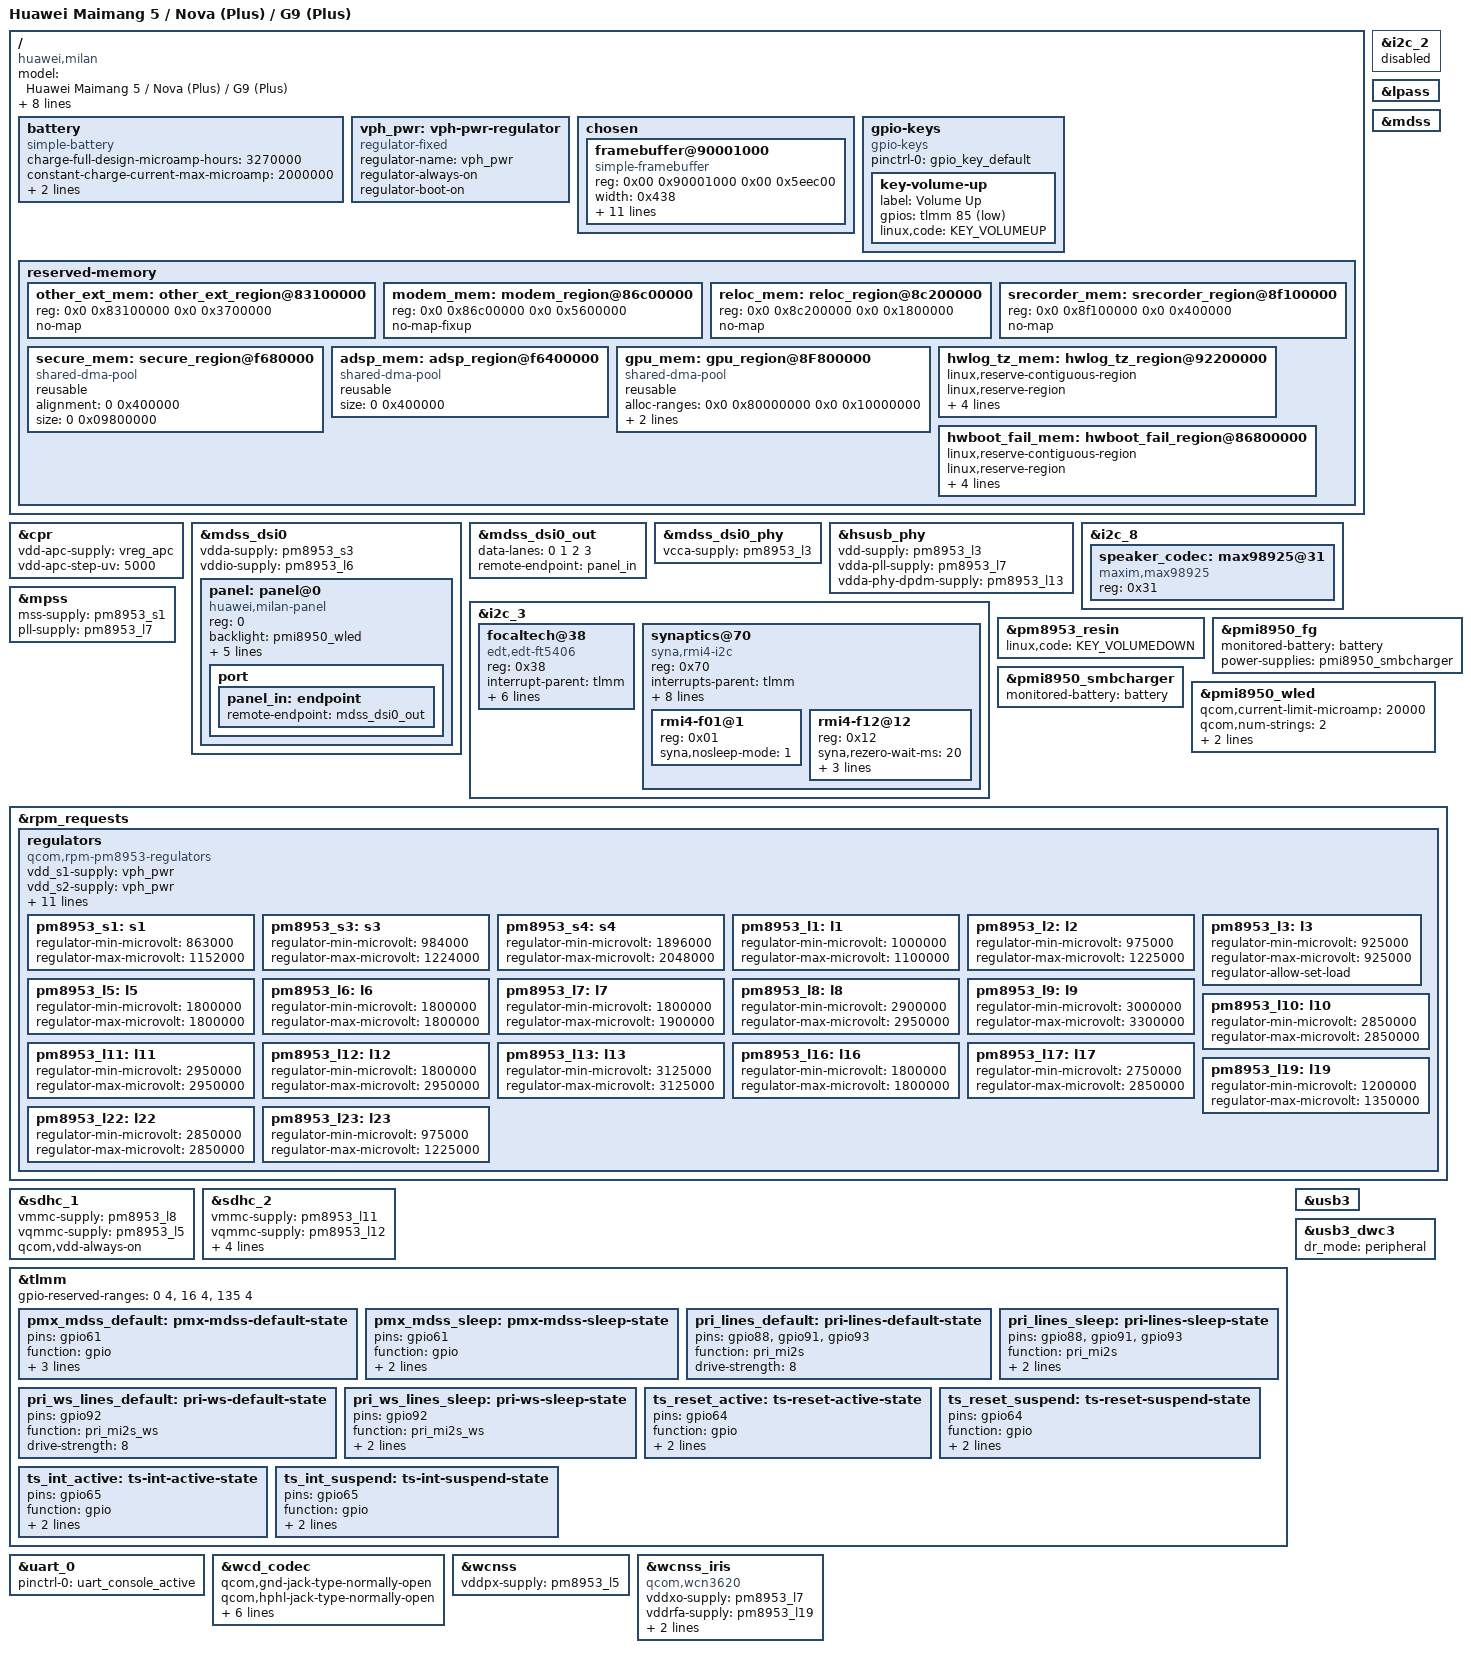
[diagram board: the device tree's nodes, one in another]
// SPDX-License-Identifier: BSD-3-Clause
/*
 * Copyright (c) 2023, bzy-080408<Bzy080408@outlook.com>
 * Copyright (c) 2023, Clrs17<2318678921@qq.com>
 */
/dts-v1/;

#include "msm8953.dtsi"
#include "pm8953.dtsi"
#include "pmi8950.dtsi"
#include <dt-bindings/gpio/gpio.h>
#include <dt-bindings/interrupt-controller/irq.h>
#include <dt-bindings/leds/common.h>


/ {
	model = "Huawei Maimang 5 / Nova (Plus) / G9 (Plus)";
	compatible = "huawei,milan", "qcom,msm8953", "lk2nd,device";
	qcom,msm-id = <293 0x0>;
	qcom,board-id = <8000 0>, <8001 0>, <8002 0>, <8003 0>, <8016 0>,
			<8017 0>, <8018 0>, <8019 0>, <8032 0>, <8033 0>,
			<8035 0>, <8048 0>, <8049 0>, <8050 0>, <8051 0>,
			<8066 0>, <8064 0>, <8067 0>, <8080 0>, <8082 0>,
			<8083 0>, <8098 0>, <8099 0>, <8114 0>, <8130 0>;
	chassis-type = "handset";
	
	battery: battery {
		compatible = "simple-battery";
		charge-full-design-microamp-hours = <3270000>;
		constant-charge-current-max-microamp = <2000000>;
		voltage-min-design-microvolt = <3400000>;
		voltage-max-design-microvolt = <4400000>;
	};
	
	vph_pwr: vph-pwr-regulator {
		compatible = "regulator-fixed";
		regulator-name = "vph_pwr";
		regulator-always-on;
		regulator-boot-on;
	};

	chosen {
		#address-cells = <2>;
		#size-cells = <2>;
		ranges;

		framebuffer@90001000 {
			compatible = "simple-framebuffer";
			reg = <0x00 0x90001000 0x00 0x5eec00>;
			width = <0x438>;
			height = <0x780>;
			stride = <0xca8>;
			format = "r8g8b8";

			power-domains = <&gcc MDSS_GDSC>;

			clocks = <&gcc GCC_MDSS_AHB_CLK>,
					 <&gcc GCC_MDSS_AXI_CLK>,
					 <&gcc GCC_MDSS_VSYNC_CLK>,
					 <&gcc GCC_MDSS_MDP_CLK>,
					 <&gcc GCC_MDSS_BYTE0_CLK>,
					 <&gcc GCC_MDSS_PCLK0_CLK>,
					 <&gcc GCC_MDSS_ESC0_CLK>;
		};
	};

	gpio-keys {
		compatible = "gpio-keys";
		
		pinctrl-0 = <&gpio_key_default>;
		pinctrl-names = "default";
		key-volume-up {
			label = "Volume Up";
			gpios = <&tlmm 85 GPIO_ACTIVE_LOW>;
			linux,code = <KEY_VOLUMEUP>;
		};
	};

	reserved-memory {
		#address-cells = <2>;
		#size-cells = <2>;
		ranges;

		other_ext_mem: other_ext_region@83100000 {
			reg = <0x0 0x83100000 0x0 0x3700000>;
			no-map;
		};


		modem_mem: modem_region@86c00000 {
			reg = <0x0 0x86c00000 0x0 0x5600000>;
			no-map-fixup;
		};
		
		reloc_mem: reloc_region@8c200000 {
			reg = <0x0 0x8c200000 0x0 0x1800000>;
			no-map;
		};
		srecorder_mem: srecorder_region@8f100000 {
			reg = <0x0 0x8f100000 0x0 0x400000>;
			no-map;
		};

		secure_mem: secure_region@f680000 {
			compatible = "shared-dma-pool";
			reusable;
			alignment = <0 0x400000>;
			size = <0 0x09800000>;
		};

		adsp_mem: adsp_region@f6400000 {
			compatible = "shared-dma-pool";
			reusable;
			size = <0 0x400000>;
		};

		gpu_mem: gpu_region@8F800000 {
			compatible = "shared-dma-pool";
			reusable;
			alloc-ranges = <0x0 0x80000000 0x0 0x10000000>;
			alignment = <0 0x400000>;
			size = <0 0x800000>;
		};

		hwlog_tz_mem: hwlog_tz_region@92200000 {
			linux,reserve-contiguous-region;
			linux,reserve-region;
			linux,remove-completely;
			no-map;
			reg = <0x0 0x92200000 0x0 0x0100000>;
			label = "hwlog_tz_mem";
		};

		hwboot_fail_mem: hwboot_fail_region@86800000 {
			linux,reserve-contiguous-region;
			linux,reserve-region;
			linux,remove-completely;
			no-map;
			reg = <0x0 0x86800000 0x0 0x0100000>;
			label = "hwboot_fail_mem";
		};
	};
};

&cpr {
	vdd-apc-supply = <&vreg_apc>;
	vdd-apc-step-uv = <5000>;
};

&mdss_dsi0 {
	status = "okay";

	vdda-supply = <&pm8953_s3>;
	vddio-supply = <&pm8953_l6>;

	panel: panel@0 {
		compatible = "huawei,milan-panel";
		reg = <0>;

		backlight = <&pmi8950_wled>;

		pinctrl-names = "default", "sleep";
		pinctrl-0 = <&pmx_mdss_default>;
		pinctrl-1 = <&pmx_mdss_sleep>;

		reset-gpios = <&tlmm 61 GPIO_ACTIVE_LOW>;

		vsp-supply = <&lab_vreg>;
		vsn-supply = <&ibb_vreg>;

		port {
			panel_in: endpoint {
				remote-endpoint = <&mdss_dsi0_out>;
			};
		};
	};
};

&mdss_dsi0_out {
	data-lanes = <0 1 2 3>;
	remote-endpoint = <&panel_in>;
};

&mdss_dsi0_phy {
	vcca-supply = <&pm8953_l3>;

	status = "okay";
};

&hsusb_phy {
	vdd-supply = <&pm8953_l3>;
	vdda-pll-supply = <&pm8953_l7>;
	vdda-phy-dpdm-supply = <&pm8953_l13>;

	status = "okay";
};
&i2c_2 {
	status = "disable";
};
&i2c_3 {
	status = "okay";
	focaltech@38 {
		compatible = "edt,edt-ft5406", "edt,edt-ft5x06";
		reg = <0x38>;

		interrupt-parent = <&tlmm>;
		interrupts = <65 IRQ_TYPE_EDGE_FALLING>;

		reset-gpios = <&tlmm 64 GPIO_ACTIVE_LOW>;

		vcc-supply = <&pm8953_l10>;
		iovcc-supply = <&pm8953_l6>;

		touchscreen-size-x = <1080>;
		touchscreen-size-y = <1920>;
	};

	synaptics@70 {
		reg = <0x70>;
		compatible = "syna,rmi4-i2c";
		interrupts-parent = <&tlmm>;
		interrupts-extended = <&tlmm 65 IRQ_TYPE_EDGE_FALLING>;

		#address-cells = <1>;
		#size-cells = <0>;

		vdd-supply = <&pm8953_l10>;
		vio-supply = <&pm8953_l6>;

		pinctrl-names = "init", "suspend";
		pinctrl-0 = <&ts_reset_active &ts_int_active>;
		pinctrl-1 = <&ts_reset_suspend &ts_int_suspend>;
		syna,reset-delay-ms = <200>;
		syna,startup-delay-ms = <500>;

		rmi4-f01@1 {
			reg = <0x01>;
			syna,nosleep-mode = <1>;
		};

		rmi4-f12@12 {
			reg = <0x12>;
			syna,rezero-wait-ms = <20>;
			syna,sensor-type = <1>;
			touchscreen-x-mm = <68>;
			touchscreen-y-mm = <122>;
		};
	};
};


&i2c_8 {
	status = "okay";
	speaker_codec: max98925@31 {
		compatible = "maxim,max98925";
		reg = <0x31>;
	};
};

&lpass {
	status = "okay";
};

&mdss {
	status = "okay";
};

&mpss {
	status = "okay";
	mss-supply = <&pm8953_s1>;
	pll-supply = <&pm8953_l7>;
};


&pm8953_resin {
	linux,code = <KEY_VOLUMEDOWN>;
	status = "okay";
};

&pmi8950_fg {
	monitored-battery = <&battery>;
	power-supplies = <&pmi8950_smbcharger>;

	status = "okay";
};

&pmi8950_smbcharger {
	monitored-battery = <&battery>;
	status = "okay";
};

&pmi8950_wled {
	qcom,current-limit-microamp = <20000>;
	qcom,num-strings = <2>;
	qcom,external-pfet;
	qcom,cabc;
	status = "okay";
};

&rpm_requests {
	regulators {
		compatible = "qcom,rpm-pm8953-regulators";
		vdd_s1-supply = <&vph_pwr>;
		vdd_s2-supply = <&vph_pwr>;
		vdd_s3-supply = <&vph_pwr>;
		vdd_s4-supply = <&vph_pwr>;
		vdd_s5-supply = <&vph_pwr>;
		vdd_s6-supply = <&vph_pwr>;
		vdd_s7-supply = <&vph_pwr>;
		vdd_l1-supply = <&pm8953_s3>;
		vdd_l2_l3-supply = <&pm8953_s3>;
		vdd_l4_l5_l6_l7_l16_l19-supply = <&pm8953_s4>;
		vdd_l8_l11_l12_l13_l14_l15-supply = <&vph_pwr>;
		vdd_l9_l10_l17_l18_l22-supply = <&vph_pwr>;
		vdd_l23-supply = <&pm8953_s3>;

		pm8953_s1: s1 {
			regulator-min-microvolt = <863000>;
			regulator-max-microvolt = <1152000>;
		};

		pm8953_s3: s3 {
			regulator-min-microvolt = <984000>;
			regulator-max-microvolt = <1224000>;
		};

		pm8953_s4: s4 {
			regulator-min-microvolt = <1896000>;
			regulator-max-microvolt = <2048000>;
		};

		pm8953_l1: l1 {
			regulator-min-microvolt = <1000000>;
			regulator-max-microvolt = <1100000>;
		};

		pm8953_l2: l2 {
			regulator-min-microvolt = <975000>;
			regulator-max-microvolt = <1225000>;
		};

		pm8953_l3: l3 {
			regulator-min-microvolt = <925000>;
			regulator-max-microvolt = <925000>;
			regulator-allow-set-load;
		};

		pm8953_l5: l5 {
			regulator-min-microvolt = <1800000>;
			regulator-max-microvolt = <1800000>;
		};

		pm8953_l6: l6 {
			regulator-min-microvolt = <1800000>;
			regulator-max-microvolt = <1800000>;
		};

		pm8953_l7: l7 {
			regulator-min-microvolt = <1800000>;
			regulator-max-microvolt = <1900000>;
		};

		pm8953_l8: l8 {
			regulator-min-microvolt = <2900000>;
			regulator-max-microvolt = <2950000>;
		};

		pm8953_l9: l9 {
			regulator-min-microvolt = <3000000>;
			regulator-max-microvolt = <3300000>;
		};

		pm8953_l10: l10 {
			regulator-min-microvolt = <2850000>;
			regulator-max-microvolt = <2850000>;
		};

		pm8953_l11: l11 {
			regulator-min-microvolt = <2950000>;
			regulator-max-microvolt = <2950000>;
		};

		pm8953_l12: l12 {
			regulator-min-microvolt = <1800000>;
			regulator-max-microvolt = <2950000>;
		};

		pm8953_l13: l13 {
			regulator-min-microvolt = <3125000>;
			regulator-max-microvolt = <3125000>;
		};

		pm8953_l16: l16 {
			regulator-min-microvolt = <1800000>;
			regulator-max-microvolt = <1800000>;
		};

		pm8953_l17: l17 {
			regulator-min-microvolt = <2750000>;
			regulator-max-microvolt = <2850000>;
		};

		pm8953_l19: l19 {
			regulator-min-microvolt = <1200000>;
			regulator-max-microvolt = <1350000>;
		};

		pm8953_l22: l22 {
			regulator-min-microvolt = <2850000>;
			regulator-max-microvolt = <2850000>;
		};

		pm8953_l23: l23 {
			regulator-min-microvolt = <975000>;
			regulator-max-microvolt = <1225000>;
		};
	};
};

&sdhc_1 {
	vmmc-supply = <&pm8953_l8>;
	vqmmc-supply = <&pm8953_l5>;
	qcom,vdd-always-on;

	status = "okay";
};

&sdhc_2 {
	vmmc-supply = <&pm8953_l11>;
	vqmmc-supply = <&pm8953_l12>;

	pinctrl-names = "default", "sleep";
	pinctrl-0 = <&sdc2_clk_on &sdc2_cmd_on &sdc2_data_on &sdc2_cd_on>;
	pinctrl-1 = <&sdc2_clk_off &sdc2_cmd_off &sdc2_data_off &sdc2_cd_off>;

	status = "okay";
};

&tlmm {
	gpio-reserved-ranges = <0 4>, <16 4>, <135 4>;

	pmx_mdss_default: pmx-mdss-default-state {
		pins = "gpio61";
		function = "gpio";
		drive-strength = <8>;
		bias-disable;
		output-high;
	};

	pmx_mdss_sleep: pmx-mdss-sleep-state {
		pins = "gpio61";
		function = "gpio";
		drive-strength = <2>;
		bias-pull-down;
	};

	pri_lines_default: pri-lines-default-state {
		pins = "gpio88", "gpio91", "gpio93";
		function = "pri_mi2s";
		drive-strength = <8>;
	};

	pri_lines_sleep: pri-lines-sleep-state {
		pins = "gpio88", "gpio91", "gpio93";
		function = "pri_mi2s";
		drive-strength = <2>;
		bias-pull-down;
	};

	pri_ws_lines_default: pri-ws-default-state {
		pins = "gpio92";
		function = "pri_mi2s_ws";
		drive-strength = <8>;
	};

	pri_ws_lines_sleep: pri-ws-sleep-state {
		pins = "gpio92";
		function = "pri_mi2s_ws";
		drive-strength = <2>;
		bias-pull-down;
	};

	ts_reset_active: ts-reset-active-state {
		pins = "gpio64";
		function = "gpio";
		drive-strength = <8>;
		bias-pull-up;
	};

	ts_reset_suspend: ts-reset-suspend-state {
		pins = "gpio64";
		function = "gpio";
		drive-strength = <2>;
		bias-pull-up;
	};

	ts_int_active: ts-int-active-state {
		pins = "gpio65";
		function = "gpio";
		drive-strength = <8>;
		bias-pull-up;
	};

	ts_int_suspend: ts-int-suspend-state {
		pins = "gpio65";
		function = "gpio";
		drive-strength = <2>;
		bias-pull-down;
	};
};

&uart_0 {
	pinctrl-names = "default";
	pinctrl-0 = <&uart_console_active>;
	status = "okay";
};

&usb3 {
	status = "okay";
};

&usb3_dwc3 {
	dr_mode = "peripheral";
};

&wcd_codec {
	qcom,gnd-jack-type-normally-open;
	qcom,hphl-jack-type-normally-open;
	qcom,mbhc-vthreshold-high = <75 150 237 450 500>;
	qcom,mbhc-vthreshold-low = <75 150 237 450 500>;
	qcom,micbias1-ext-cap;

	vdd-cdc-io-supply = <&pm8953_l5>;
	vdd-cdc-tx-rx-cx-supply = <&pm8953_s4>;
	vdd-micbias-supply = <&pm8953_l13>;

	status = "okay";
};

&wcnss {
	status = "okay";
	vddpx-supply = <&pm8953_l5>;
};

&wcnss_iris {
	compatible = "qcom,wcn3620";
	vddxo-supply = <&pm8953_l7>;
	vddrfa-supply = <&pm8953_l19>;
	vddpa-supply = <&pm8953_l9>;
	vdddig-supply = <&pm8953_l5>;
};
